# MSS_RCM_MSS_RCM_53208000h register map
Vendor: Texas Instruments
Registers are 32-bit, read-write, reset 0x0 unless marked. A register's access mark holds for its fields unless they carry their own. Offsets are as the file gives them; [hi:lo] are bit positions; {n}, {i} and the like mark numbered series.

## MSS_RCM (part 2 of 2)
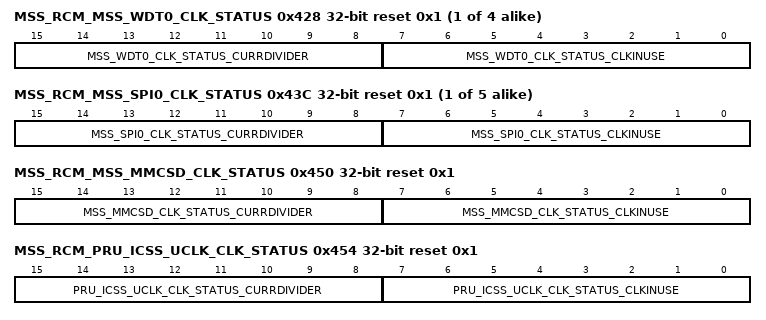
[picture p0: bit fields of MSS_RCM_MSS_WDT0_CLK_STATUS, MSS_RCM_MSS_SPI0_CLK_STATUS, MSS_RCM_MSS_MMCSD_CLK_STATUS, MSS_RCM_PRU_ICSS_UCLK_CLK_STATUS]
{0x428+4i} MSS_RCM_MSS_WDT{i}_CLK_STATUS ro reset 0x1 (i=0..3) — Clock source selection and Divider Value of respective clock.
  [15:8] MSS_WDT{i}_CLK_STATUS_CURRDIVIDER — Status shows the current divider value choosen for corresponding WDT
  [7:0] MSS_WDT{i}_CLK_STATUS_CLKINUSE — Status shows the source clock slected for Corresponding WDT based on one hot encoding technique.
{0x43C+4i} MSS_RCM_MSS_SPI{i}_CLK_STATUS ro reset 0x1 (i=0..4) — Clock source selection and Divider Value of respective clock.
  [15:8] MSS_SPI{i}_CLK_STATUS_CURRDIVIDER — Status shows the current divider value choosen for Corresponding SPI
  [7:0] MSS_SPI{i}_CLK_STATUS_CLKINUSE — Status shows the source clock slected for Corresponding SPI based on one hot encoding technique.
0x450 MSS_RCM_MSS_MMCSD_CLK_STATUS ro reset 0x1 — Clock source selection and Divider Value of respective clock.
  [15:8] MSS_MMCSD_CLK_STATUS_CURRDIVIDER — Status shows the current divider value choosen for MMCSD
  [7:0] MSS_MMCSD_CLK_STATUS_CLKINUSE — Status shows the source clock slected for MMCSD based on one hot encoding technique.
0x454 MSS_RCM_PRU_ICSS_UCLK_CLK_STATUS ro reset 0x1 — Clock source selection and Divider Value of respective clock.
  [15:8] PRU_ICSS_UCLK_CLK_STATUS_CURRDIVIDER — Status shows the current divider value choosen for ICSSM_UCLK
  [7:0] PRU_ICSS_UCLK_CLK_STATUS_CLKINUSE — Status shows the source clock slected for ICSSM_UCLK based on one hot encoding technique.
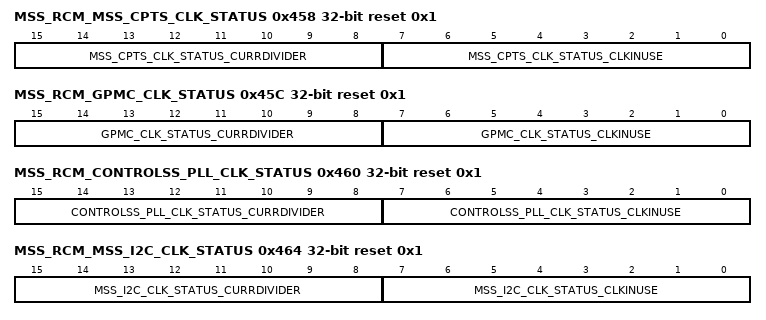
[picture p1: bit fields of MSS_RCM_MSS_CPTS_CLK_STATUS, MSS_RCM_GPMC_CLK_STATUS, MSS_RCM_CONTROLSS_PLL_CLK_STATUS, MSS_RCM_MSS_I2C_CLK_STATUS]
0x458 MSS_RCM_MSS_CPTS_CLK_STATUS ro reset 0x1 — Clock source selection and Divider Value of respective clock.
  [15:8] MSS_CPTS_CLK_STATUS_CURRDIVIDER — Status shows the current divider value choosen for CPTS
  [7:0] MSS_CPTS_CLK_STATUS_CLKINUSE — Status shows the source clock slected for CPTS based on one hot encoding technique.
0x45C MSS_RCM_GPMC_CLK_STATUS ro reset 0x1 — Clock source selection and Divider Value of respective clock.
  [15:8] GPMC_CLK_STATUS_CURRDIVIDER — Status shows the current divider value choosen for GPMC
  [7:0] GPMC_CLK_STATUS_CLKINUSE — Status shows the source clock slected for GPMC based on one hot encoding technique.
0x460 MSS_RCM_CONTROLSS_PLL_CLK_STATUS ro reset 0x1 — Clock source selection and Divider Value of respective clock.
  [15:8] CONTROLSS_PLL_CLK_STATUS_CURRDIVIDER — Status shows the current divider value choosen for CONTROLSS_PLL
  [7:0] CONTROLSS_PLL_CLK_STATUS_CLKINUSE — Status shows the source clock slected for CONTROLSS_PLL based on one hot encoding technique.
0x464 MSS_RCM_MSS_I2C_CLK_STATUS ro reset 0x1 — Clock source selection and Divider Value of respective clock.
  [15:8] MSS_I2C_CLK_STATUS_CURRDIVIDER — Status shows the current divider value choosen for I2C
  [7:0] MSS_I2C_CLK_STATUS_CLKINUSE — Status shows the source clock slected for I2C based on one hot encoding technique.
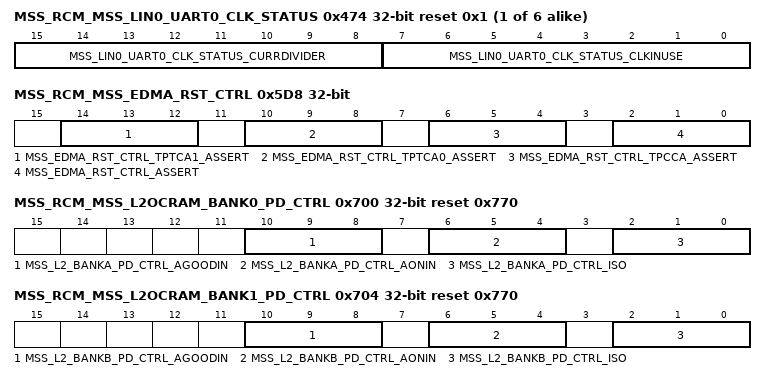
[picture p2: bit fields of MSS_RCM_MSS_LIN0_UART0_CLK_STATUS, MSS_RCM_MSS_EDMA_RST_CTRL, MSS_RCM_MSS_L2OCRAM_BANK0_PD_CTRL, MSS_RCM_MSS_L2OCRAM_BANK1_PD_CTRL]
{0x474+4i} MSS_RCM_MSS_LIN{i}_UART{i}_CLK_STATUS ro reset 0x1 (i=0..5) — Clock source selection and Divider Value of respective clock.
  [15:8] MSS_LIN{i}_UART{i}_CLK_STATUS_CURRDIVIDER — Status shows the current divider value choosen for corresponding UART and LIN
  [7:0] MSS_LIN{i}_UART{i}_CLK_STATUS_CLKINUSE — Status shows the source clock slected for corresponding UART and LIN based on one hot encoding technique.
0x48C MSS_RCM_MSS_RGMII_CLK_STATUS ro reset 0x100 — Clock source selection and Divider Value of respective clock.
  [15:8] MSS_RGMII_CLK_STATUS_CURRDIVIDER — Status shows the current divider value choosen for RGMII
0x490 MSS_RCM_MSS_MII100_CLK_STATUS ro reset 0x900 — RGMII_50_CLK_STATUS.
  [15:8] MSS_MII100_CLK_STATUS_CURRDIVIDER — Status shows the current divider value choosen for MII100
0x494 MSS_RCM_MSS_MII10_CLK_STATUS ro reset 0x6300 — RGMII_5_CLK_STATUS.
  [15:8] MSS_MII10_CLK_STATUS_CURRDIVIDER — Status shows the current divider value choosen for MII10
0x49C MSS_RCM_MMC0_32K_CLK_STATUS ro reset 0x30C00 — Clock source selection and Divider Value of respective clock.
  [17:8] MMC0_32K_CLK_STATUS_CURRDIVIDER — Status shows the current divider value choosen for XTAL_32K
0x4A0 MSS_RCM_TEMPSENSE_32K_CLK_STATUS ro reset 0x30C00 — Clock source selection and Divider Value of respective clock.
  [17:8] TEMPSENSE_32K_CLK_STATUS_CURRDIVIDER — Status shows the current divider value choosen for XTAL_32K
0x4A4 MSS_RCM_MSS_ELM_CLK_STATUS ro reset 0x300 — MSS_ELM_CLK_STATUS.
  [15:8] MSS_ELM_CLK_STATUS_CURRDIVIDER — Status shows the current divider value choosen for ELM
0x500 MSS_RCM_MSS_R5SS0_POR_RST_CTRL0 — This register is used to Reset respective IP.
  [2:0] MSS_CR5SS_POR_RST_CTRL0_ASSERT — This feature is for debug purpose only. Software needs to ensure the state of the Device/IP before configuring.write pulse bit field:Writing 3'b111 will assert por reset to R5SS Read is always 000
0x504 MSS_RCM_MSS_R5SS0_POR_RST_CTRL1 — R5SS POR Reset.
  [2:0] MSS_CR5SS_POR_RST_CTRL1_ASSERT — This feature is for debug purpose only. Software needs to ensure the state of the Device/IP before configuring.write pulse bit field:Writing 3'b111 will assert por reset to R5SS Read is always 000
0x508 MSS_RCM_MSS_CR5SSA_RST_CTRL0 — R5SS POR Reset.
  [2:0] MSS_CR5SSA_RST_CTRL0_ASSERT — This feature is for debug purpose only. Software needs to ensure the state of the Device/IP before configuring.write pulse bit field:Writing 3'b111 will reset CORE0 and MSS_CORE0_VIM
0x50C MSS_RCM_MSS_CR5SSA_RST_CTRL1 — Core 0 Global Reset.
  [2:0] MSS_CR5SSA_RST_CTRL1_ASSERT — This feature is for debug purpose only. Software needs to ensure the state of the Device/IP before configuring.write pulse bit field:Writing 3'b111 will reset CORE0 and MSS_CORE0_VIM
0x510 MSS_RCM_MSS_CR5SSB_RST_CTRL0 — Core 0 Global Reset.
  [2:0] MSS_CR5SSB_RST_CTRL0_ASSERT — This feature is for debug purpose only. Software needs to ensure the state of the Device/IP before configuring.write pulse bit field:Writing 3'b111 will reset CORE1 and MSS_CORE1_VIM
0x514 MSS_RCM_MSS_CR5SSB_RST_CTRL1 — Core 1 Global Reset.
  [2:0] MSS_CR5SSB_RST_CTRL1_ASSERT — This feature is for debug purpose only. Software needs to ensure the state of the Device/IP before configuring.write pulse bit field:Writing 3'b111 will reset CORE1 and MSS_CORE1_VIM
0x518 MSS_RCM_MSS_R5SS0_CORE0_RST_CTRL0 — Core 1 Global Reset.
  [2:0] MSS_CR5A_RST_CTRL0_ASSERT — This feature is for debug purpose only. Software needs to ensure the state of the Device/IP before configuring.write pulse bit field:Writing 3'b111 will reset CORE0 only
0x51C MSS_RCM_MSS_R5SS0_CORE0_RST_CTRL1 — Core 0 Local Reset.
  [2:0] MSS_CR5A_RST_CTRL1_ASSERT — This feature is for debug purpose only. Software needs to ensure the state of the Device/IP before configuring.write pulse bit field:Writing 3'b111 will reset CORE0 only
0x520 MSS_RCM_MSS_R5SS0_CORE1_RST_CTRL0 — Core 0 Local Reset.
  [2:0] MSS_CR5B_RST_CTRL0_ASSERT — This feature is for debug purpose only. Software needs to ensure the state of the Device/IP before configuring.write pulse bit field:Writing 3'b111 will reset CORE1 only
0x524 MSS_RCM_MSS_R5SS0_CORE1_RST_CTRL1 — Core 1 Local Reset.
  [2:0] MSS_CR5B_RST_CTRL1_ASSERT — This feature is for debug purpose only. Software needs to ensure the state of the Device/IP before configuring.write pulse bit field:Writing 3'b111 will reset CORE1 only
0x528 MSS_RCM_MSS_VIMA_RST_CTRL0 — Core 1 Local Reset.
  [2:0] MSS_VIMA_RST_CTRL0_ASSERT — This feature is for debug purpose only. Software needs to ensure the state of the Device/IP before configuring. Writing 3'b111 will reset MSS_CORE0_VIM Writing 3'b000 will deassert the reset
0x52C MSS_RCM_MSS_VIMA_RST_CTRL1 — This register is used to Reset respective IP.
  [2:0] MSS_VIMA_RST_CTRL1_ASSERT — This feature is for debug purpose only. Software needs to ensure the state of the Device/IP before configuring. Writing 3'b111 will reset MSS_CORE0_VIM Writing 3'b000 will deassert the reset
0x530 MSS_RCM_MSS_VIMB_RST_CTRL0 — This register is used to Reset respective IP.
  [2:0] MSS_VIMB_RST_CTRL0_ASSERT — This feature is for debug purpose only. Software needs to ensure the state of the Device/IP before configuring. Writing 3'b111 will reset MSS_CORE1_VIM
0x534 MSS_RCM_MSS_VIMB_RST_CTRL1 — This register is used to Reset respective IP.
  [2:0] MSS_VIMB_RST_CTRL1_ASSERT — This feature is for debug purpose only. Software needs to ensure the state of the Device/IP before configuring. Writing 3'b111 will reset MSS_CORE1_VIM
0x538 MSS_RCM_MSS_CRC_RST_CTRL — This register is used to Reset respective IP.
  [2:0] MSS_CRC_RST_CTRL_ASSERT — This feature is for debug purpose only. Software needs to ensure the state of the Device/IP before configuring. Writing 3'b111 will reset MCRC
{0x53C+4i} MSS_RCM_MSS_RTI{i}_RST_CTRL (i=0..3) — This register is used to Reset respective IP.
  [2:0] MSS_RTI{i}_RST_CTRL_ASSERT — This feature is for debug purpose only. Software needs to ensure the state of the Device/IP before configuring. Writing 3'b111 will reset corresponding RTI
{0x54C+4i} MSS_RCM_MSS_WDT{i}_RST_CTRL (i=0..3) — This register is used to Reset respective IP.
  [2:0] MSS_WDT{i}_RST_CTRL_ASSERT — This feature is for debug purpose only. Software needs to ensure the state of the Device/IP before configuring. Writing 3'b111 will reset corresponding WDT
0x55C MSS_RCM_MSS_ESM_RST_CTRL — This register is used to Reset respective IP.
  [2:0] MSS_ESM_RST_CTRL_ASSERT — This feature is for debug purpose only. Software needs to ensure the state of the Device/IP before configuring. Writing 3'b111 will reset ESM
{0x560+4i} MSS_RCM_MSS_DCC{i}_RST_CTRL (i=0..3) — This register is used to Reset respective IP.
  [2:0] MSS_DCC{i}_RST_CTRL_ASSERT — This feature is for debug purpose only. Software needs to ensure the state of the Device/IP before configuring. Writing 3'b111 will reset DCC{i+1}
{0x570+4i} MSS_RCM_MSS_SPI{i}_RST_CTRL (i=0..4) — This register is used to Reset respective IP.
  [2:0] MSS_SPI{i}_RST_CTRL_ASSERT — This feature is for debug purpose only. Software needs to ensure the state of the Device/IP before configuring. Writing 3'b111 will reset Corresponding SPI
0x584 MSS_RCM_MSS_QSPI_RST_CTRL — This register is used to Reset respective IP.
  [2:0] MSS_QSPI_RST_CTRL_ASSERT — This feature is for debug purpose only. Software needs to ensure the state of the Device/IP before configuring. Writing 3'b111 will reset QSPI
{0x588+4i} MSS_RCM_MSS_MCAN{i}_RST_CTRL (i=0..3) — This register is used to Reset respective IP.
  [2:0] MSS_MCAN{i}_RST_CTRL_ASSERT — This feature is for debug purpose only. Software needs to ensure the state of the Device/IP before configuring. Writing 3'b111 will reset corresponding MCAN
{0x598+4i} MSS_RCM_MSS_I2C{i}_RST_CTRL (i=0..3) — This register is used to Reset respective IP.
  [2:0] MSS_I2C{i}_RST_CTRL_ASSERT — This feature is for debug purpose only. Software needs to ensure the state of the Device/IP before configuring. Writing 3'b111 will reset corresponding I2C
{0x5A8+4i} MSS_RCM_MSS_UART{i}_RST_CTRL (i=0..5) — This register is used to Reset respective IP.
  [2:0] MSS_UART{i}_RST_CTRL_ASSERT — This feature is for debug purpose only. Software needs to ensure the state of the Device/IP before configuring. Writing 3'b111 will reset corresponding UART instance
{0x5C0+4i} MSS_RCM_MSS_LIN{i}_RST_CTRL (i=0..4) — This register is used to Reset respective IP.
  [2:0] MSS_LIN{i}_RST_CTRL_ASSERT — This feature is for debug purpose only. Software needs to ensure the state of the Device/IP before configuring. Writing 3'b111 will reset corresponding LIN
0x5D8 MSS_RCM_MSS_EDMA_RST_CTRL — This register is used to Reset respective IP.
  [14:12] MSS_EDMA_RST_CTRL_TPTCA1_ASSERT — This feature is for debug purpose only. Software needs to ensure the state of the Device/IP before configuring. Writing 3'b111 will reset MSS_TPTCA1
  [10:8] MSS_EDMA_RST_CTRL_TPTCA0_ASSERT — This feature is for debug purpose only. Software needs to ensure the state of the Device/IP before configuring. Writing 3'b111 will reset MSS_TPTCA0
  [6:4] MSS_EDMA_RST_CTRL_TPCCA_ASSERT — This feature is for debug purpose only. Software needs to ensure the state of the Device/IP before configuring. Writing 3'b111 will reset MSS_TPCCA
  [2:0] MSS_EDMA_RST_CTRL_ASSERT — This feature is for debug purpose only. Software needs to ensure the state of the Device/IP before configuring. Writing 3'b111 will reset EDMA
0x5DC MSS_RCM_MSS_INFRA_RST_CTRL — This register is used to Reset respective IP.
  [2:0] MSS_INFRA_RST_CTRL_ASSERT — This feature is for debug purpose only. Software needs to ensure the state of the Device/IP before configuring. Writing 3'b111 will reset MSS INFRA
0x5E0 MSS_RCM_MSS_CPSW_RST_CTRL — This register is used to Reset respective IP.
  [2:0] MSS_CPSW_RST_CTRL_ASSERT — This feature is for debug purpose only. Software needs to ensure the state of the Device/IP before configuring. Writing 3'b111 will reset MSS CPSW
0x5E4 MSS_RCM_MSS_PRU_ICSS_RST_CTRL — This register is used to Reset respective IP.
  [2:0] MSS_PRU_ICSS_RST_CTRL_ASSERT — This feature is for debug purpose only. Software needs to ensure the state of the Device/IP before configuring. Writing 3'b111 will reset MSS ICSSM
0x5E8 MSS_RCM_MSS_MMCSD_RST_CTRL — This register is used to Reset respective IP.
  [2:0] MSS_MMCSD_RST_CTRL_ASSERT — This feature is for debug purpose only. Software needs to ensure the state of the Device/IP before configuring. Writing 3'b111 will reset MMCSD
{0x5EC+4i} MSS_RCM_MSS_GPIO{i}_RST_CTRL (i=0..3) — This register is used to Reset respective IP.
  [2:0] MSS_GPIO{i}_RST_CTRL_ASSERT — This feature is for debug purpose only. Software needs to ensure the state of the Device/IP before configuring. Writing 3'b111 will reset corresponding GPIO module
0x5FC MSS_RCM_MSS_SPINLOCK_RST_CTRL — This register is used to Reset respective IP.
  [2:0] MSS_SPINLOCK_RST_CTRL_ASSERT — This feature is for debug purpose only. Software needs to ensure the state of the Device/IP before configuring. Writing 3'b111 will reset SPINLOCK
0x600 MSS_RCM_GPMC_RST_CTRL — This register is used to Reset respective IP.
  [2:0] GPMC_RST_CTRL_ASSERT — This feature is for debug purpose only. Software needs to ensure the state of the Device/IP before configuring. Writing 3'b111 will reset GPMC
0x604 MSS_RCM_TEMPSENSE_32K_RST_CTRL — This register is used to Reset respective IP.
  [2:0] TEMPSENSE_32K_RST_CTRL_ASSERT — This feature is for debug purpose only. Software needs to ensure the state of the Device/IP before configuring. Writing 3'b111 will reset TEMPSENSE**Note: This bit will only be reset by PORz.
0x608 MSS_RCM_MSS_ELM_RST_CTRL — This register is used to Reset respective IP.
  [2:0] MSS_ELM_RST_CTRL_ASSERT — This feature is for debug purpose only. Software needs to ensure the state of the Device/IP before configuring. Writing 3'b111 will reset ELM
0x700 MSS_RCM_MSS_L2OCRAM_BANK0_PD_CTRL reset 0x770 — S/W control to Powers down the L2 Bank 0 and disconnect from Interconnect. AON AGOOD 0 or ISO =1 causes bus disconnect.
  [10:8] MSS_L2_BANKA_PD_CTRL_AGOODIN — SW control for power signal 'AGOODIN' for MSS_L2_BANKA
  [6:4] MSS_L2_BANKA_PD_CTRL_AONIN — SW control for power signal 'AONIN' for MSS_L2_BANKA
  [2:0] MSS_L2_BANKA_PD_CTRL_ISO — SW control for power signal 'ISO' for MSS_L2_BANKA.
0x704 MSS_RCM_MSS_L2OCRAM_BANK1_PD_CTRL reset 0x770 — S/W control to Powers down the L2 Bank 1 and disconnect from Interconnect.
  [10:8] MSS_L2_BANKB_PD_CTRL_AGOODIN — SW control for power signal 'AGOODIN' for MSS_L2_BANKB
  [6:4] MSS_L2_BANKB_PD_CTRL_AONIN — SW control for power signal 'AONIN' for MSS_L2_BANKB
  [2:0] MSS_L2_BANKB_PD_CTRL_ISO — SW control for power signal 'ISO' for MSS_L2_BANKB
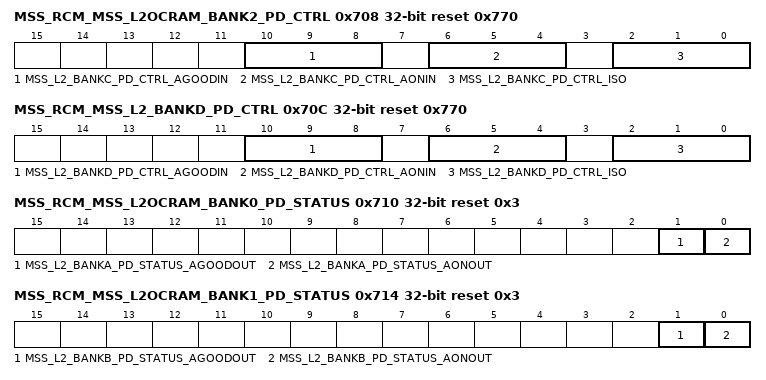
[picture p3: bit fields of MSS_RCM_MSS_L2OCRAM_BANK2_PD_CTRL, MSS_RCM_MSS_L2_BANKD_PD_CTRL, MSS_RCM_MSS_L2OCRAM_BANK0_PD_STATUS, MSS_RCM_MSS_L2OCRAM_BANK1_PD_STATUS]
0x708 MSS_RCM_MSS_L2OCRAM_BANK2_PD_CTRL reset 0x770 — S/W control to Powers down the L2 Bank 2 and disconnect from Interconnect.
  [10:8] MSS_L2_BANKC_PD_CTRL_AGOODIN — SW control for power signal 'AGOODIN' for MSS_L2_BANKC
  [6:4] MSS_L2_BANKC_PD_CTRL_AONIN — SW control for power signal 'AONIN' for MSS_L2_BANKC
  [2:0] MSS_L2_BANKC_PD_CTRL_ISO — SW control for power signal 'ISO' for MSS_L2_BANKC
0x70C MSS_RCM_MSS_L2_BANKD_PD_CTRL reset 0x770 — S/W control to Powers down the L2 Bank 3 and disconnect from Interconnect.
  [10:8] MSS_L2_BANKD_PD_CTRL_AGOODIN — SW control for power signal 'AGOODIN' for MSS_L2_BANKD
  [6:4] MSS_L2_BANKD_PD_CTRL_AONIN — SW control for power signal 'AONIN' for MSS_L2_BANKD
  [2:0] MSS_L2_BANKD_PD_CTRL_ISO — SW control for power signal 'ISO' for MSS_L2_BANKD
0x710 MSS_RCM_MSS_L2OCRAM_BANK0_PD_STATUS ro reset 0x3 — L2 Bank PD status. Pgood out observation.
  [1] MSS_L2_BANKA_PD_STATUS_AGOODOUT — SW status indicating the 'pgoodin' of MSS_L2_BANKA
  [0] MSS_L2_BANKA_PD_STATUS_AONOUT — SW status indicating the 'ponin' of MSS_L2_BANKA
0x714 MSS_RCM_MSS_L2OCRAM_BANK1_PD_STATUS ro reset 0x3 — L2 Bank PD status. Pgood out observation.
  [1] MSS_L2_BANKB_PD_STATUS_AGOODOUT — SW status indicating the 'pgoodin' of MSS_L2_BANKB
  [0] MSS_L2_BANKB_PD_STATUS_AONOUT — SW status indicating the 'ponin' of MSS_L2_BANKB
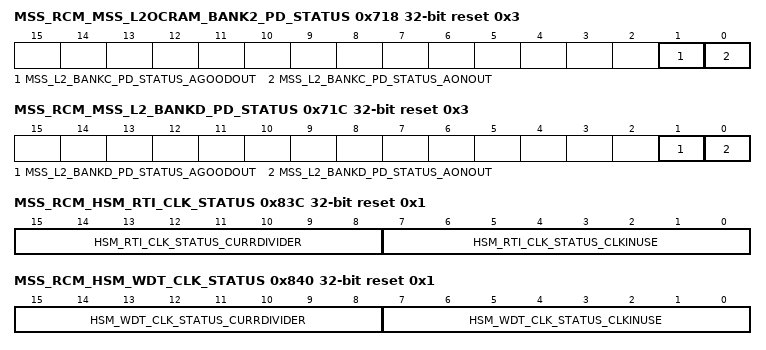
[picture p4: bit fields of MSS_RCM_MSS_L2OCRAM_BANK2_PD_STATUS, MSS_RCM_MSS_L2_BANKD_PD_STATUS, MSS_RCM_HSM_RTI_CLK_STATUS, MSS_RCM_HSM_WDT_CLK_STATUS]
0x718 MSS_RCM_MSS_L2OCRAM_BANK2_PD_STATUS ro reset 0x3 — L2 Bank PD status. Pgood out observation.
  [1] MSS_L2_BANKC_PD_STATUS_AGOODOUT — SW status indicating the 'pgoodin' of MSS_L2_BANKC
  [0] MSS_L2_BANKC_PD_STATUS_AONOUT — SW status indicating the 'ponin' of MSS_L2_BANKC
0x71C MSS_RCM_MSS_L2_BANKD_PD_STATUS ro reset 0x3 — L2 Bank PD status. Pgood out observation.
  [1] MSS_L2_BANKD_PD_STATUS_AGOODOUT — SW status indicating the 'pgoodin' of MSS_L2_BANKD
  [0] MSS_L2_BANKD_PD_STATUS_AONOUT — SW status indicating the 'ponin' of MSS_L2_BANKD
0x800 MSS_RCM_HSM_RTIA_CLK_SRC_SEL — This Register is used for selecting the clock source for Corresponding root clock.
  [11:0] HSM_RTIA_CLK_SRC_SEL_CLKSRCSEL — Select line for selecting source clock for HSM_Corresponding RTI.Data should be loaded as multibit. For example: if '0x5' should be selected then '0x555' should be configured to the register.Use the following values to select clk src-0x000 - WUCPUCLK0x111 - XTALCLK0x222 - SYS_CLK0x333 - DPLL_PER_HSDIV0_CLKOUT10x444 - RCCLK10M0x555 - RCCLK10M0x666 - EXT_REFCLK0x777 - RCCLK32K
0x804 MSS_RCM_HSM_WDT_CLK_SRC_SEL — This Register is used for selecting the clock source for Corresponding root clock.
  [11:0] HSM_WDT_CLK_SRC_SEL_CLKSRCSEL — Select line for selecting source clock for HSM_WDT.Data should be loaded as multibit. For example: if '0x5' should be selected then '0x555' should be configured to the register.Use the following values to select clk src-0x000 - WUCPUCLK0x111 - XTALCLK0x222 - SYS_CLK0x333 - DPLL_PER_HSDIV0_CLKOUT10x444 - RCCLK10M0x555 - RCCLK10M0x666 - EXT_REFCLK0x777 - RCCLK32K
0x808 MSS_RCM_HSM_RTC_CLK_SRC_SEL reset 0x777 — This Register is used for selecting the clock source for Corresponding root clock.
  [11:0] HSM_RTC_CLK_SRC_SEL_CLKSRCSEL — Select line for selecting source clock for HSM_RTC.Data should be loaded as multibit. For example: if '0x5' should be selected then '0x555' should be configured to the register.Use the following values to select clk src-0x000 - WUCPUCLK0x111 - XTALCLK0x222 - SYS_CLK0x333 - DPLL_PER_HSDIV0_CLKOUT10x444 - RCCLK10M0x555 - RCCLK10M0x666 - EXT_REFCLK0x777 - RCCLK32K
0x80C MSS_RCM_HSM_DMTA_CLK_SRC_SEL — This Register is used for selecting the clock source for Corresponding root clock.
  [11:0] HSM_DMTA_CLK_SRC_SEL_CLKSRCSEL — Select line for selecting source clock for HSM_DMTA.Data should be loaded as multibit. For example: if '0x5' should be selected then '0x555' should be configured to the register.Use the following values to select clk src-0x000 - WUCPUCLK0x111 - XTALCLK0x222 - SYS_CLK0x333 - DPLL_PER_HSDIV0_CLKOUT10x444 - RCCLK10M0x555 - RCCLK10M0x666 - EXT_REFCLK0x777 - RCCLK32K
0x810 MSS_RCM_HSM_DMTB_CLK_SRC_SEL — This Register is used for selecting the clock source for Corresponding root clock.
  [11:0] HSM_DMTB_CLK_SRC_SEL_CLKSRCSEL — Select line for selecting source clock for HSM_DMTB.Data should be loaded as multibit. For example: if '0x5' should be selected then '0x555' should be configured to the register.Use the following values to select clk src-0x000 - WUCPUCLK0x111 - XTALCLK0x222 - SYS_CLK0x333 - DPLL_PER_HSDIV0_CLKOUT10x444 - RCCLK10M0x555 - RCCLK10M0x666 - EXT_REFCLK0x777 - RCCLK32K
0x814 MSS_RCM_HSM_RTI_CLK_DIV_VAL — This Register is used to select the Divider value for respective clk.
  [11:0] HSM_RTI_CLK_DIV_VAL_CLKDIVR — Divider value HSM RTI selected clock.To set the divider value of [n+1] configure the register to value of '0xnnn'.Data should be loaded as multibit. For example: if divider value of '0x9' is required then '0x888' should be configured to the register.
0x818 MSS_RCM_HSM_WDT_CLK_DIV_VAL — This Register is used to select the Divider value for respective clk.
  [11:0] HSM_WDT_CLK_DIV_VAL_CLKDIVR — Divider value HSM WDT selected clock.To set the divider value of [n+1] configure the register to value of '0xnnn'.Data should be loaded as multibit. For example: if divider value of '0x9' is required then '0x888' should be configured to the register.
0x81C MSS_RCM_HSM_RTC_CLK_DIV_VAL — This Register is used to select the Divider value for respective clk.
  [11:0] HSM_RTC_CLK_DIV_VAL_CLKDIVR — Divider value HSM RTC selected clock.To set the divider value of [n+1] configure the register to value of '0xnnn'.Data should be loaded as multibit. For example: if divider value of '0x9' is required then '0x888' should be configured to the register.
0x820 MSS_RCM_HSM_DMTA_CLK_DIV_VAL — This Register is used to select the Divider value for respective clk.
  [11:0] HSM_DMTA_CLK_DIV_VAL_CLKDIVR — Divider value HSM DMTA selected clock.To set the divider value of [n+1] configure the register to value of '0xnnn'.Data should be loaded as multibit. For example: if divider value of '0x9' is required then '0x888' should be configured to the register.
0x824 MSS_RCM_HSM_DMTB_CLK_DIV_VAL — This Register is used to select the Divider value for respective clk.
  [11:0] HSM_DMTB_CLK_DIV_VAL_CLKDIVR — Divider value HSM DMTB selected clock.To set the divider value of [n+1] configure the register to value of '0xnnn'.Data should be loaded as multibit. For example: if divider value of '0x9' is required then '0x888' should be configured to the register.
0x828 MSS_RCM_HSM_RTI_CLK_GATE — This Register is used to enable clk gating for the respective clk.
  [2:0] HSM_RTI_CLK_GATE_GATED — Writing 3'b111 will gate clock for HSM RTI
0x82C MSS_RCM_HSM_WDT_CLK_GATE — This Register is used to enable clk gating for the respective clk.
  [2:0] HSM_WDT_CLK_GATE_GATED — Writing 3'b111 will gate clock for HSM WDT
0x830 MSS_RCM_HSM_RTC_CLK_GATE — This Register is used to enable clk gating for the respective clk.
  [2:0] HSM_RTC_CLK_GATE_GATED — Writing 3'b111 will gate clock for HSM RTC
0x834 MSS_RCM_HSM_DMTA_CLK_GATE — This Register is used to enable clk gating for the respective clk.
  [2:0] HSM_DMTA_CLK_GATE_GATED — Writing 3'b111 will gate clock for HSM DMTA
0x838 MSS_RCM_HSM_DMTB_CLK_GATE — This Register is used to enable clk gating for the respective clk.
  [2:0] HSM_DMTB_CLK_GATE_GATED — Writing 3'b111 will gate clock for HSM DMTB
0x83C MSS_RCM_HSM_RTI_CLK_STATUS ro reset 0x1 — Clock source selection and Divider Value of respective clock.
  [15:8] HSM_RTI_CLK_STATUS_CURRDIVIDER — Status shows the current divider value choosen for HSM_RTI
  [7:0] HSM_RTI_CLK_STATUS_CLKINUSE — Status shows the source clock slected for HSM_RTI based on one hot encoding technique.
0x840 MSS_RCM_HSM_WDT_CLK_STATUS ro reset 0x1 — Clock source selection and Divider Value of respective clock.
  [15:8] HSM_WDT_CLK_STATUS_CURRDIVIDER — Status shows the current divider value choosen for HSM_WDT
  [7:0] HSM_WDT_CLK_STATUS_CLKINUSE — Status shows the source clock slected for HSM_WDT based on one hot encoding technique.
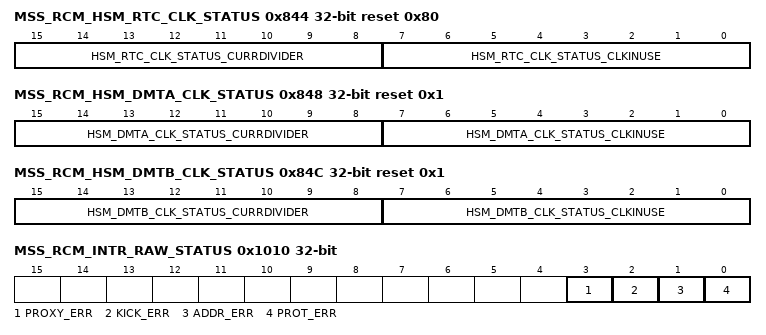
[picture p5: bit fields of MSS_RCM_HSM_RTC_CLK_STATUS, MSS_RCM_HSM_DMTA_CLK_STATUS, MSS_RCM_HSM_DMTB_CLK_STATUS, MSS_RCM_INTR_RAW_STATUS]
0x844 MSS_RCM_HSM_RTC_CLK_STATUS ro reset 0x80 — Clock source selection and Divider Value of respective clock.
  [15:8] HSM_RTC_CLK_STATUS_CURRDIVIDER — Status shows the current divider value choosen for HSM_RTC
  [7:0] HSM_RTC_CLK_STATUS_CLKINUSE — Status shows the source clock slected for HSM_RTC based on one hot encoding technique.
0x848 MSS_RCM_HSM_DMTA_CLK_STATUS ro reset 0x1 — Clock source selection and Divider Value of respective clock.
  [15:8] HSM_DMTA_CLK_STATUS_CURRDIVIDER — Status shows the current divider value choosen for HSM_DMTA
  [7:0] HSM_DMTA_CLK_STATUS_CLKINUSE — Status shows the source clock slected for HSM_DMTA based on one hot encoding technique.
0x84C MSS_RCM_HSM_DMTB_CLK_STATUS ro reset 0x1 — Clock source selection and Divider Value of respective clock.
  [15:8] HSM_DMTB_CLK_STATUS_CURRDIVIDER — Status shows the current divider value choosen for HSM_DMTB
  [7:0] HSM_DMTB_CLK_STATUS_CLKINUSE — Status shows the source clock slected for HSM_DMTB based on one hot encoding technique.
0x1008 MSS_RCM_LOCK0_KICK0 — - KICK0 component.
  [31:0] LOCK0_KICK0 — - KICK0 component
0x100C MSS_RCM_LOCK0_KICK1 — - KICK1 component.
  [31:0] LOCK0_KICK1 — - KICK1 component
0x1010 MSS_RCM_INTR_RAW_STATUS access not given — Interrupt Raw Status/Set Register.
  [3] PROXY_ERR — Proxy0 access violation error. Raw status is read. Write a 1 to set the status. Writing a 0 has no effect. (access R/W1TS)
  [2] KICK_ERR — Kick access violation error. Raw status is read. Write a 1 to set the status. Writing a 0 has no effect. (access R/W1TS)
  [1] ADDR_ERR — Addressing violation error. Raw status is read. Write a 1 to set the status. Writing a 0 has no effect. (access R/W1TS)
  [0] PROT_ERR — Protection violation error. Raw status is read. Write a 1 to set the status. Writing a 0 has no effect. (access R/W1TS)
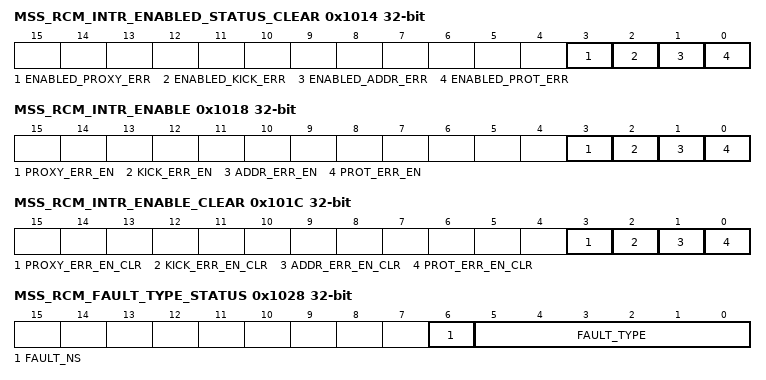
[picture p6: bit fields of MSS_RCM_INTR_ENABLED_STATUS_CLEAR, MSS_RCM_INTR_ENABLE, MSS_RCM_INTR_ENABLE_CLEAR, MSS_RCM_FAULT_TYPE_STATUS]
0x1014 MSS_RCM_INTR_ENABLED_STATUS_CLEAR access not given — Interrupt Enabled Status/Clear register.
  [3] ENABLED_PROXY_ERR — Proxy0 access violation error. Enabled status is read. Write a 1 to clear the status. Writing a 0 has no effect. (access R/W1TC)
  [2] ENABLED_KICK_ERR — Kick access violation error. Enabled status is read. Write a 1 to clear the status. Writing a 0 has no effect. (access R/W1TC)
  [1] ENABLED_ADDR_ERR — Addressing violation error. Enabled status is read. Write a 1 to clear the status. Writing a 0 has no effect. (access R/W1TC)
  [0] ENABLED_PROT_ERR — Protection violation error. Enabled status is read. Write a 1 to clear the status. Writing a 0 has no effect. (access R/W1TC)
0x1018 MSS_RCM_INTR_ENABLE access not given — Interrupt Enable register.
  [3] PROXY_ERR_EN — Proxy0 access violation error enable. Write a 1 to set the enable. Writing a 0 has no effect. (access R/W1TS)
  [2] KICK_ERR_EN — Kick access violation error enable. Write a 1 to set the enable. Writing a 0 has no effect. (access R/W1TS)
  [1] ADDR_ERR_EN — Addressing violation error enable. Write a 1 to set the enable. Writing a 0 has no effect. (access R/W1TS)
  [0] PROT_ERR_EN — Protection violation error enable. Write a 1 to set the enable. Writing a 0 has no effect. (access R/W1TS)
0x101C MSS_RCM_INTR_ENABLE_CLEAR access not given — Interrupt Enable Clear register.
  [3] PROXY_ERR_EN_CLR — Proxy0 access violation error enable clear. Write a 1 to clear the enable. Writing a 0 has no effect. (access R/W1TC)
  [2] KICK_ERR_EN_CLR — Kick access violation error enable clear. Write a 1 to clear the enable. Writing a 0 has no effect. (access R/W1TC)
  [1] ADDR_ERR_EN_CLR — Addressing violation error enable clear. Write a 1 to clear the enable. Writing a 0 has no effect. (access R/W1TC)
  [0] PROT_ERR_EN_CLR — Protection violation error enable clear. Write a 1 to clear the enable. Writing a 0 has no effect. (access R/W1TC)
0x1020 MSS_RCM_EOI — EOI register.
  [7:0] EOI_VECTOR — EOI vector value. Write this with interrupt distribution value in the chip.
0x1024 MSS_RCM_FAULT_ADDRESS ro — Fault Address register.
  [31:0] FAULT_ADDR — Fault Address.
0x1028 MSS_RCM_FAULT_TYPE_STATUS ro — Fault Type Status register.
  [6] FAULT_NS — Non-secure access.
  [5:0] FAULT_TYPE — Fault Type 10_0000 = Supervisor read fault - priv = 1 dir = 1 dtype != 1 01_0000 = Supervisor write fault - priv = 1 dir = 0 00_1000 = Supervisor execute fault - priv = 1 dir = 1 dtype = 1 00_0100 = User read fault - priv = 0 dir = 1 dtype = 1 00_0010 = User write fault - priv = 0 dir = 0 00_0001 = User execute fault - priv = 0 dir = 1 dtype = 1 00_0000 = No fault
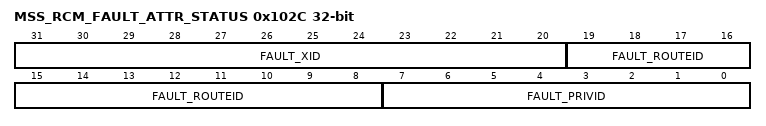
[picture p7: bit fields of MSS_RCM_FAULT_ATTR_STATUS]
0x102C MSS_RCM_FAULT_ATTR_STATUS ro — Fault Attribute Status register.
  [31:20] FAULT_XID — XID.
  [19:8] FAULT_ROUTEID — Route ID.
  [7:0] FAULT_PRIVID — Privilege ID.
0x1030 MSS_RCM_FAULT_CLEAR wo — Fault Clear register.
  [0] FAULT_CLR — Fault clear. Writing a 1 clears the current fault. Writing a 0 has no effect.
